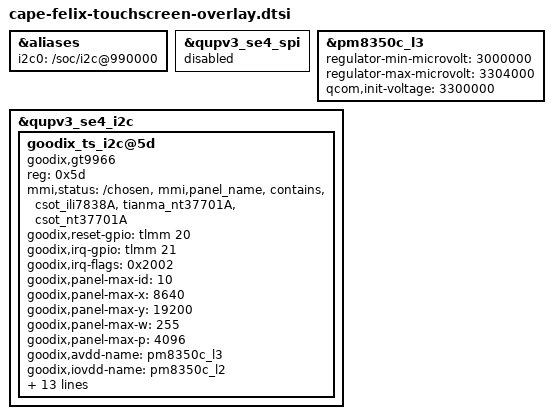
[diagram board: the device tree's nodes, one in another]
/*
 * Copyright (c) 2019, The Linux Foundation. All rights reserved.
 *
 * This program is free software; you can redistribute it and/or modify
 * it under the terms of the GNU General Public License version 2 and
 * only version 2 as published by the Free Software Foundation.
 *
 * This program is distributed in the hope that it will be useful,
 * but WITHOUT ANY WARRANTY; without even the implied warranty of
 * MERCHANTABILITY or FITNESS FOR A PARTICULAR PURPOSE.  See the
 * GNU General Public License for more details.
 */
#include <dt-bindings/clock/qcom,rpmh.h>

&aliases {
	i2c0 = "/soc/i2c@990000";
};

&qupv3_se4_spi {
	status = "disabled";
};

&pm8350c_l3 {
	regulator-min-microvolt = <3000000>;
	regulator-max-microvolt = <3304000>;
	qcom,init-voltage = <3300000>;
};

&qupv3_se4_i2c {
	#address-cells = <1>;
	#size-cells = <0>;

	status = "ok";

	goodix_ts_i2c@5d {
		status = "ok";
		compatible = "goodix,gt9966";
		reg = <0x5d>;
		mmi,status = "/chosen","mmi,panel_name","contains","csot_ili7838A","tianma_nt37701A", "csot_nt37701A";
		goodix,reset-gpio = <&tlmm 20 0x0>;
		goodix,irq-gpio = <&tlmm 21 0x2002>;
		goodix,irq-flags = <0x2002>; /* 1:trigger rising, 2:trigger falling;*/
		goodix,panel-max-id = <10>;
		goodix,panel-max-x = <8640>;
		goodix,panel-max-y = <19200>;
		goodix,panel-max-w = <255>;
		goodix,panel-max-p = <4096>;
		goodix,avdd-name = "pm8350c_l3";
		goodix,iovdd-name = "pm8350c_l2";
		goodix,pen-enable;
		goodix,film_mode-ctrl;
		goodix,sensitivity-ctrl;
		goodix,edge-ctrl;
		pinctrl-names = "pmx_ts_active", "pmx_ts_suspend", "pmx_ts_release";
		pinctrl-0 = <&ts_active>;
		pinctrl-1 = <&ts_int_suspend &ts_reset_suspend>;
		pinctrl-2 = <&ts_release>;
		mmi,enable-gestures;
		mmi,power-off-suspend;
		mmi,usb-charger-detection;
		goodix,report_rate-ctrl;
		goodix,interpolation-ctrl;
		mmi,refresh-rate-update;
	};
};
